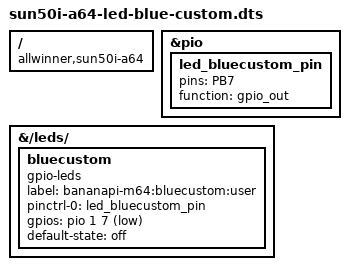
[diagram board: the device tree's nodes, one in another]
/*
* DevDotNet.ORG <anton@devdotnet.org>
*
* MIT License
* 
* Device: Blue led, https://www.dfrobot.com/product-492.html
* Module      Connector
* Control    <-  PB7
*/

/dts-v1/;
/plugin/;

/ {
	compatible = "allwinner,sun50i-a64";

	fragment@0 {
		target = <&pio>;
		__overlay__ {
			led_bluecustom_pin: led_bluecustom_pin {
				pins = "PB7";
				function = "gpio_out";
			};
		};
	};

	fragment@1 {
		target-path = "/leds/";
		__overlay__ {
			bluecustom {
				compatible = "gpio-leds";
				label = "bananapi-m64:bluecustom:user";			 	
				pinctrl-names = "default";
				pinctrl-0 = <&led_bluecustom_pin>;
				gpios = <&pio 1 7 1>; /* PB7 */
				default-state = "off";
			};
		};
	};
};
